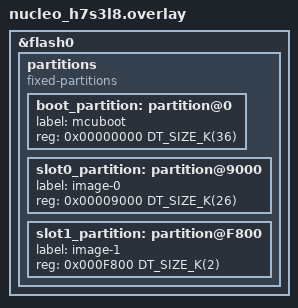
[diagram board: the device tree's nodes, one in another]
// / {
//     chosen {
//         zephyr,code-partition = &slot0_partition;
//     };
//     };
    
    &flash0 {
        // compatible = "st,stm32h7-flash";
        // reg = <0x08000000 0x10000>; /* 64KB Flash */
        // label = "FLASH";
    
        partitions {
            compatible = "fixed-partitions";
            #address-cells = <1>;
            #size-cells = <1>;
    
            boot_partition: partition@0 {
                label = "mcuboot";
                reg = <0x00000000 DT_SIZE_K(36)>; /* 32KB for MCUboot */
            };
    
            slot0_partition: partition@9000 {
                label = "image-0";
                // reg = <0x0000C000 DT_SIZE_K(8)>; /* 16B for Application */
                reg = <0x00009000 DT_SIZE_K(26)>; /* 16B for Application */
            };
    
            slot1_partition: partition@F800 {
                label = "image-1";
                // reg = <0x000E000 DT_SIZE_K(8)>; /* 16KB for Secondary Application Slot */
                reg = <0x000F800 DT_SIZE_K(2)>; /* 16KB for Secondary Application Slot */
            };
        };
    };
